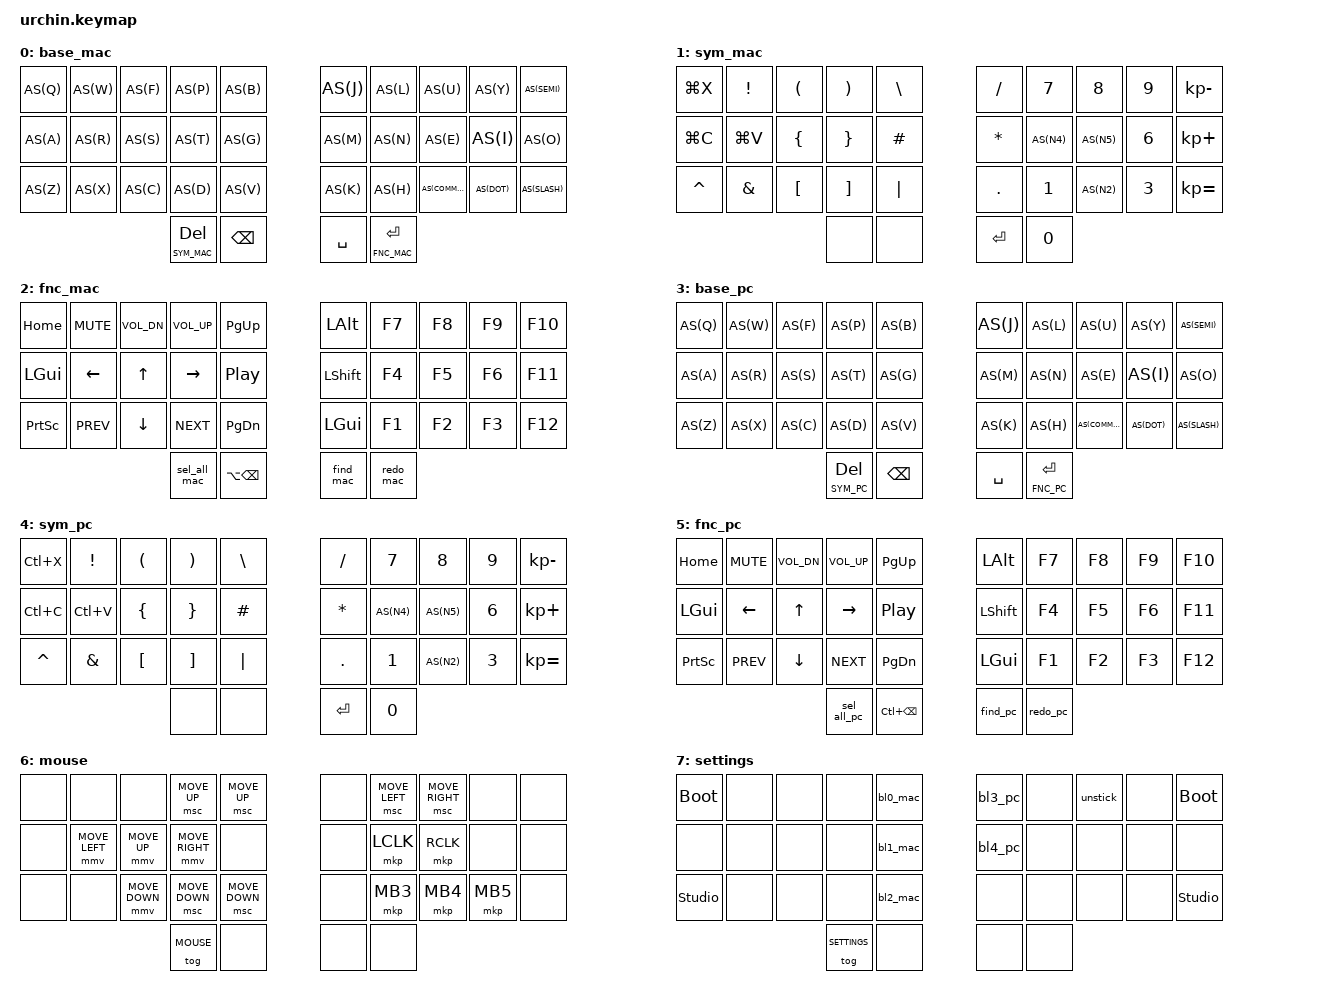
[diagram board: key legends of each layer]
#include <behaviors.dtsi>
#include <dt-bindings/zmk/keys.h>
#include <dt-bindings/zmk/bt.h>
#include <dt-bindings/zmk/outputs.h>

#define ZMK_POINTING_DEFAULT_MOVE_VAL 900   // default: 600
#define ZMK_POINTING_DEFAULT_SCRL_VAL 12    // default: 10
#include <dt-bindings/zmk/pointing.h>

// Autoshift Macro
#define AS(keycode) &as LS(keycode) keycode     

// Layer definitions
#define BASE_MAC 0

#define SYM_MAC 1
#define FNC_MAC 2
#define BASE_PC 3
#define SYM_PC 4
#define FNC_PC 5
#define MOUSE 6
#define SETTINGS 7
// -----------------

/ {
	behaviors {
		// Enables holding the first mod-tap key
		// by performing a tap-release-hold sequence.
		// To use it: "&qt KEYCODE1 KEYCODE2"
			qt: quick_tap {
				compatible = "zmk,behavior-hold-tap";
				#binding-cells = <2>;
			flavor = "hold-preferred";
			tapping-term-ms = <200>;
			quick-tap-ms = <200>;
			bindings = <&kp>, <&kp>;
		};
		as: auto_shift {
            compatible = "zmk,behavior-hold-tap";
            #binding-cells = <2>;
            tapping-term-ms = <255>;
            quick-tap-ms = <0>;
            flavor = "tap-preferred";
            bindings = <&kp>, <&kp>;
        };
			mmv: mouse_move {
	            compatible = "zmk,behavior-input-two-axis";
	            x-input-code = <INPUT_REL_X>;
	            y-input-code = <INPUT_REL_Y>;
	            time-to-max-speed-ms = <240>;
	            acceleration-exponent = <1>;
	        };
	};

		macros {
			// sometimes my device thinks a modifier is being held down
			// pressing all modifiers fixes it.
			unstick: unstick {
				compatible = "zmk,behavior-macro";
				#binding-cells = <0>;
				bindings = <&kp LSHIFT &kp RSHIFT &kp LCTRL &kp RCTRL &kp LALT &kp RALT &kp LGUI &kp RGUI>;
			};

			bl0_mac: bl0_mac {
				compatible = "zmk,behavior-macro";
				#binding-cells = <0>;
				bindings = <&bt BT_SEL 0 &to BASE_MAC>;
			};
			bl1_mac: bl1_mac {
				compatible = "zmk,behavior-macro";
				#binding-cells = <0>;
				bindings = <&bt BT_SEL 1 &to BASE_MAC>;
			};
			bl2_mac: bl2_mac {
				compatible = "zmk,behavior-macro";
				#binding-cells = <0>;
				bindings = <&bt BT_SEL 2 &to BASE_MAC>;
			};
			bl3_pc: bl3_pc {
				compatible = "zmk,behavior-macro";
				#binding-cells = <0>;
				bindings = <&bt BT_SEL 3 &to BASE_PC>;
			};
			bl4_pc: bl4_pc {
				compatible = "zmk,behavior-macro";
				#binding-cells = <0>;
				bindings = <&bt BT_SEL 4 &to BASE_PC>;
			};

			sel_all_mac: sel_all_mac {
				compatible = "zmk,behavior-macro";
				#binding-cells = <0>;
				bindings = <&kp LG(A)>;
			};
			find_mac: find_mac {
				compatible = "zmk,behavior-macro";
				#binding-cells = <0>;
				bindings = <&kp LG(F)>;
			};
			redo_mac: redo_mac {
				compatible = "zmk,behavior-macro";
				#binding-cells = <0>;
				bindings = <&kp LG(LS(Z))>;
			};
			sel_all_pc: sel_all_pc {
				compatible = "zmk,behavior-macro";
				#binding-cells = <0>;
				bindings = <&kp LC(A)>;
			};
			find_pc: find_pc {
				compatible = "zmk,behavior-macro";
				#binding-cells = <0>;
				bindings = <&kp LC(F)>;
			};
			redo_pc: redo_pc {
				compatible = "zmk,behavior-macro";
				#binding-cells = <0>;
				bindings = <&kp LC(LS(Z))>;
			};
		};

		combos {
			compatible = "zmk,combos";
			combo_mouse {
	            timeout-ms = <350>;
				require-prior-idle-ms = <0>;
				layers = <BASE_MAC BASE_PC>;
	            key-positions = <30 33>; // both outer thumb keys are held
	            bindings = <&tog MOUSE>;
	        };

			combo_settings {
				timeout-ms = <350>;
				require-prior-idle-ms = <0>;
				layers = <BASE_MAC SYM_MAC FNC_MAC BASE_PC SYM_PC FNC_PC>;
				key-positions = <30 31>; // left two thumbs: LT(SYM,DEL) + BSPC
				bindings = <&tog SETTINGS>;
			};

		    combo_esc {
	        	timeout-ms = <170>;
				require-prior-idle-ms = <450>;
				layers = <BASE_MAC BASE_PC>;
	        	key-positions = <1 2>;  // W + F
	        	bindings = <&kp ESC>;
	    		};

			combo_caps_lock {
				timeout-ms = <170>;
				require-prior-idle-ms = <450>;
				layers = <BASE_MAC BASE_PC>;
				key-positions = <2 3>;  // F + P
				bindings = <&kp CAPS>;
			};

		// Left thumb is 30
			combo_apos {
				timeout-ms = <200>;
				require-prior-idle-ms = <200>;
				layers = <BASE_MAC BASE_PC>;
				key-positions = <18 19>;  // I + O
				bindings = <&kp APOS>;
			};

			combo_dqt {
				timeout-ms = <200>;
				require-prior-idle-ms = <200>;
				layers = <BASE_MAC BASE_PC>;
				key-positions = <8 9>;  // Y + ;
				bindings = <&kp DQT>;
			};

			combo_undo_mac {
				timeout-ms = <200>;
				require-prior-idle-ms = <200>;
				layers = <BASE_MAC>;
				key-positions = <20 22>;  // Z + C
				bindings = <&kp LG(Z)>; // MacOS
			};
			combo_undo_pc {
				timeout-ms = <200>;
				require-prior-idle-ms = <200>;
				layers = <BASE_PC>;
				key-positions = <20 22>;  // Z + C
				bindings = <&kp LC(Z)>; // Linux/Windows
			};

			combo_save_mac {
				timeout-ms = <200>;
				require-prior-idle-ms = <200>;
				layers = <BASE_MAC>;
				key-positions = <20 23>;  // Z + D
				bindings = <&kp LG(S)>; // MacOS
			};
			combo_save_pc {
				timeout-ms = <200>;
				require-prior-idle-ms = <200>;
				layers = <BASE_PC>;
				key-positions = <20 23>;  // Z + D
				bindings = <&kp LC(S)>; // Linux/Windows
			};

			combo_underscore {
				timeout-ms = <200>;
				require-prior-idle-ms = <350>;
				layers = <BASE_MAC BASE_PC>;
				key-positions = <23 26>;  // D + H
				bindings = <&kp UNDERSCORE>;
			};

			combo_dash {
				timeout-ms = <200>;
				require-prior-idle-ms = <350>;
				layers = <BASE_MAC BASE_PC>;
				key-positions = <13 16>;  // T + N
				bindings = <&kp MINUS>;
			};

			combo_tab {
				timeout-ms = <170>;
				require-prior-idle-ms = <450>;
				layers = <BASE_MAC BASE_PC>;
				key-positions = <10 11>;  // A + R
				bindings = <&kp TAB>;
			};

			combo_shift {
				timeout-ms = <200>;
				require-prior-idle-ms = <200>;
				layers = <BASE_MAC BASE_PC>;
				key-positions = <0 1>;  // Q + W
				bindings = <&kp LSHIFT>;
			};

			combo_ctrl {
				timeout-ms = <200>;
				require-prior-idle-ms = <200>;
				layers = <BASE_MAC BASE_PC>;
				key-positions = <20 21>;  // Z + X
				bindings = <&kp LCTRL>;
			};

			combo_tilde {
				timeout-ms = <200>;
				require-prior-idle-ms = <300>;
				layers = <BASE_MAC BASE_PC>;
				key-positions = <3 6>;  // P + L
				bindings = <&kp TILDE>;
			};

			combo_bt_clear {
				timeout-ms = <300>;
				require-prior-idle-ms = <300>;
				layers = <SETTINGS>;
				key-positions = <30 31 32 33>;
				bindings = <&bt BT_CLR>;
			};

		};

		keymap {
			compatible = "zmk,keymap";
			base_mac {
				bindings = <
				AS(Q)   AS(W)   AS(F)   AS(P)   AS(B)          AS(J)   AS(L)   AS(U)   AS(Y)   AS(SEMI)
				AS(A)   AS(R)   AS(S)   AS(T)   AS(G)          AS(M)   AS(N)   AS(E)   AS(I)   AS(O)
				AS(Z)   AS(X)   AS(C)   AS(D)   AS(V)          AS(K)   AS(H)   AS(COMMA) AS(DOT) AS(SLASH)
								&lt SYM_MAC DEL &kp BSPC          &kp SPACE &lt FNC_MAC ENTER
				>;
			};

			sym_mac {
				bindings = <
				&kp LG(X) &kp EXCL &kp LPAR &kp RPAR &kp BSLH		    &kp SLASH &kp N7 &kp N8 &kp N9 &kp KP_MINUS
				&kp LG(C) &kp LG(V) &kp LBRC &kp RBRC &kp HASH          &kp ASTRK AS(N4) AS(N5) &kp N6 &kp KP_PLUS
				&kp CARET &kp AMPS &kp LBKT &kp RBKT &kp PIPE 	        &kp DOT &kp N1 AS(N2) &kp N3 &kp KP_EQUAL
												&none &none       &kp RET &kp N0
				>;
			};

	        fnc_mac {
	            bindings = <
	            &kp HOME  &kp C_MUTE  &kp C_VOL_DN  &kp C_VOL_UP  &kp PG_UP       &kp LALT   &kp F7    &kp F8   &kp F9   &kp F10
	            &kp LGUI  &kp LEFT    &kp UP        &kp RIGHT     &kp C_PP       &kp LSHFT &kp F4    &kp F5   &kp F6   &kp F11
	            &kp PSCRN &kp K_PREV     &kp DOWN      &kp K_NEXT      &kp PG_DN         &kp LGUI  &kp F1    &kp F2   &kp F3   &kp F12
	                                &sel_all_mac   &kp LA(BSPC)          &find_mac   &redo_mac
	            >;
	        };

			base_pc {
				bindings = <
				AS(Q)   AS(W)   AS(F)   AS(P)   AS(B)          AS(J)   AS(L)   AS(U)   AS(Y)   AS(SEMI)
				AS(A)   AS(R)   AS(S)   AS(T)   AS(G)          AS(M)   AS(N)   AS(E)   AS(I)   AS(O)
				AS(Z)   AS(X)   AS(C)   AS(D)   AS(V)          AS(K)   AS(H)   AS(COMMA) AS(DOT) AS(SLASH)
								&lt SYM_PC DEL &kp BSPC          &kp SPACE &lt FNC_PC ENTER
				>;
			};

			sym_pc {
				bindings = <
				&kp LC(X) &kp EXCL &kp LPAR &kp RPAR &kp BSLH		    &kp SLASH &kp N7 &kp N8 &kp N9 &kp KP_MINUS
				&kp LC(C) &kp LC(V) &kp LBRC &kp RBRC &kp HASH          &kp ASTRK AS(N4) AS(N5) &kp N6 &kp KP_PLUS
				&kp CARET &kp AMPS &kp LBKT &kp RBKT &kp PIPE 	        &kp DOT &kp N1 AS(N2) &kp N3 &kp KP_EQUAL
												&none &none       &kp RET &kp N0
				>;
			};

	        fnc_pc {
	            bindings = <
	            &kp HOME  &kp C_MUTE  &kp C_VOL_DN  &kp C_VOL_UP  &kp PG_UP       &kp LALT   &kp F7    &kp F8   &kp F9   &kp F10
	            &kp LGUI  &kp LEFT    &kp UP        &kp RIGHT     &kp C_PP       &kp LSHFT &kp F4    &kp F5   &kp F6   &kp F11
	            &kp PSCRN &kp K_PREV     &kp DOWN      &kp K_NEXT      &kp PG_DN         &kp LGUI  &kp F1    &kp F2   &kp F3   &kp F12
	                                &sel_all_pc   &kp LC(BSPC)          &find_pc   &redo_pc
	            >;
	        };

			mouse {
	            bindings = <
	            &none     &none      &none      &msc MOVE_UP   &msc MOVE_UP       &none     &msc MOVE_LEFT  &msc MOVE_RIGHT  &none     &none
	            &none     &mmv MOVE_LEFT  &mmv MOVE_UP  &mmv MOVE_RIGHT  &none    &none     &mkp LCLK  &mkp RCLK  &none     &none
	            &none     &none      &mmv MOVE_DOWN  &msc MOVE_DOWN  &msc MOVE_DOWN       &none     &mkp MB3  &mkp MB4  &mkp MB5  &none
	                                &tog MOUSE &none        &none     &none
	            >;
	        };

			settings {
					bindings = <
					&bootloader &none &none &none &bl0_mac               &bl3_pc &none &unstick &none &bootloader 
					&none &none &none &none      &bl1_mac 						  &bl4_pc &none &none &none &none
					&studio_unlock &none &none &none      &bl2_mac               &none &none &none &none &studio_unlock
											&tog SETTINGS &none                         &none &none 
					>;
			};
		};
};
